# SPC1169 register map
File version: 2022071043481212
CPU: cm4 r1p0, little endian, no MPU, FPU, 4 interrupt priority bits
Registers are 32-bit, read-write, reset 0x0 unless marked. A register's access mark holds for its fields unless they carry their own. Offsets are from the block's base; [hi:lo] are bit positions; {n}, {i} and the like mark numbered series; 'fields as' and 'values as' point back to an identical list.

## PWM0 (part 2 of 2)
Base 0x40002000
Same registers: PWM1 0x40002100, PWM2 0x40002200, PWM3 0x40002300
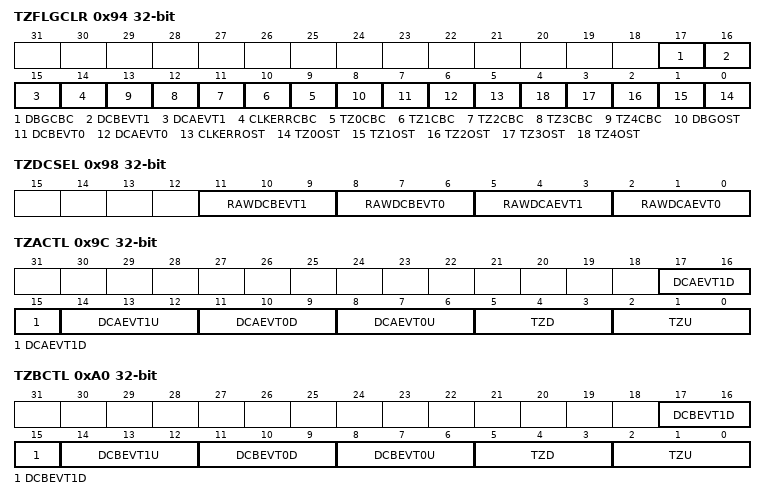
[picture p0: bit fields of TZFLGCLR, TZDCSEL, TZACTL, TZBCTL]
0x94 TZFLGCLR — Trip-Zone Flag Clear Register
  [all] fields
    0=NO_EFFECT (Write a 0 has no effect. Always reads back a 0); 1=CLEAR (Write a 1 clears the latched status. This bit is self-cleared to 0)
  [17] DBGCBC — Latched JTAG debug cycle-by-cycle trip event flag clear
  [16] DCBEVT1 — Latched digital compare B event 1 cycle-by-cycle trip flag clear
  [15] DCAEVT1 — Latched digital compare A event 1 cycle-by-cycle trip flag clear
  [14] CLKERRCBC — Latched clock error cycle-by-cycle trip event flag clear
  [n+9] TZ{n}CBC (n=0..4) — Latched TZ{n} cycle-by-cycle trip event flag clear
  [8] DBGOST — Latched JTAG debug one-shot trip event flag clear
  [7] DCBEVT0 — Latched digital output B event 0 one-shot trip flag clear
  [6] DCAEVT0 — Latched digital output A event 0 one-shot trip flag clear
  [5] CLKERROST — Latched clock error one-shot trip event flag clear
  [n] TZ{n}OST (n=0..4) — Latched TZ{n} one-shot trip event flag clear
0x98 TZDCSEL — Trip-Zone Digital Compare Event Select Register
  [11:9] RAWDCBEVT1 — Raw digital compare B event 1 option
    0=DISABLE (Event disabled); 1=DCBH_X_DCBL_LOW (DCBL=low, DCBH=don't care); 2=DCBH_X_DCBL_HIGH (DCBL=high, DCBH=don't care); 3=DCBH_LOW_DCBL_X (DCBL=don't care, DCBH=low); 4=DCBH_HIGH_DCBL_X (DCBL=don't care, DCBH=high); 5=DCBH_HIGH_DCBL_LOW (DCBL=low, DCBH=high); 6=DCBH_LOW_DCBL_HIGH (DCBL=high, DCBH=low); 7=DCBH_HIGH_DCBL_HIGH (DCBL=high, DCBH=high)
  [8:6] RAWDCBEVT0 — Raw digital compare B event 0 option
    values as RAWDCBEVT1
  [5:3] RAWDCAEVT1 — Raw digital compare A event 1 option
    0=DISABLE (Event disabled); 1=DCAH_X_DCAL_LOW (DCAL=low, DCAH=don't care); 2=DCAH_X_DCAL_HIGH (DCAL=high, DCAH=don't care); 3=DCAH_LOW_DCAL_X (DCAL=don't care, DCAH=low); 4=DCAH_HIGH_DCAL_X (DCAL=don't care, DCAH=high); 5=DCAH_HIGH_DCAL_LOW (DCAL=low, DCAH=high); 6=DCAH_LOW_DCAL_HIGH (DCAL=high, DCAH=low); 7=DCAH_HIGH_DCAL_HIGH (DCAL=high, DCAH=high)
  [2:0] RAWDCAEVT0 — Raw digital compare A event 0 option
    values as RAWDCAEVT1
0x9C TZACTL — Trip-Zone Output A Control Register
  [all] fields
    0=TRI_STATE (Set output A to high-impedance); 1=SET_LOW (Force output A to low state); 2=SET_HIGH (Force output A to high state); 3=TOGGLE (Force output A to invert current state (high->low, low->high)); 7=DO_NOTHING (Do nothing for output A)
  [17:15] DCAEVT1D — Action on output A when a digital compare A event 1 occurs and TBCNT is counting down
  [14:12] DCAEVT1U — Action on output A when a digital compare A event 1 occurs and TBCNT is counting up
  [11:9] DCAEVT0D — Action on output A when a digital compare A event 0 occurs and TBCNT is counting down
  [8:6] DCAEVT0U — Action on output A when a digital compare A event 0 occurs and TBCNT is counting up
  [5:3] TZD — Action on output A when a trip event occurs and TBCNT is counting down
  [2:0] TZU — Action on output A when a trip event occurs and TBCNT is counting up
0xA0 TZBCTL — Trip-Zone Ouput B Control Register
  [17:15] DCBEVT1D — Action on output B when a digital compare B event 1 occurs and TBCNT is counting down
    0=TRI_STATE (Set output B to high-impedance); 1=SET_HIGH (Force output B to high state); 2=SET_LOW (Force output B to low state); 3=TOGGLE (Force output B to invert current state (high->low, low->high)); 7=DO_NOTHING (Do nothing for output B)
  [14:12] DCBEVT1U — Action on output B when a digital compare B event 1 occurs and TBCNT is counting up
    0=TRI_STATE (Set output B to high-impedance); 1=SET_LOW (Force output B to low state); 2=SET_HIGH (Force output B to high state); 3=TOGGLE (Force output B to invert current state (high->low, low->high)); 7=DO_NOTHING (Do nothing for output B)
  [11:9] DCBEVT0D — Action on output B when a digital compare B event 0 occurs and TBCNT is counting down
    values as DCBEVT1U
  [8:6] DCBEVT0U — Action on output B when a digital compare B event 0 occurs and TBCNT is counting up
    values as DCBEVT1U
  [5:3] TZD — Action on output B when a trip event occurs and TBCNT is counting down
    values as DCBEVT1U
  [2:0] TZU — Action on output B when a trip event occurs and TBCNT is counting up
    values as DCBEVT1U
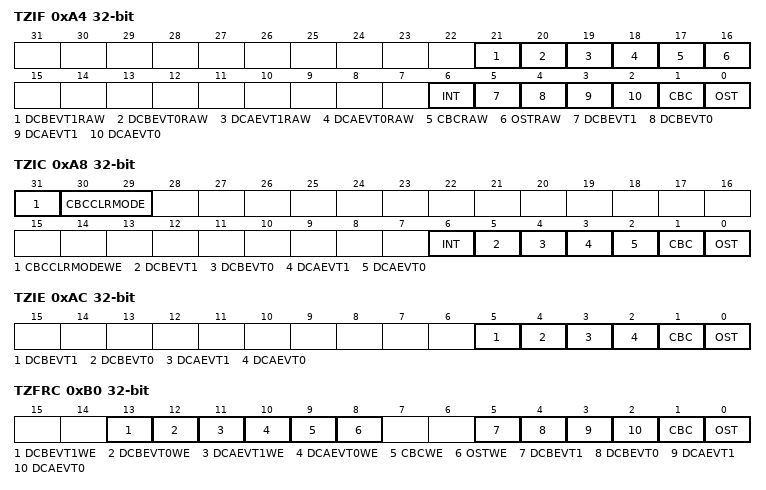
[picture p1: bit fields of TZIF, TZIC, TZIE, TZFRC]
0xA4 TZIF ro — Trip-Zone Interrupt Flag Register
  [21] DCBEVT1RAW — Digital compare B event 1 raw interrupt flag
    0=NOT_OCCUR (DCBEVT1 event does not occur); 1=OCCUR (DCBEVT1 event occurred. It is cleared by writing 1 to TZIC.DCBEVT1.)
  [20] DCBEVT0RAW — Digital compare B event 0 raw interrupt flag
    0=NOT_OCCUR (DCBEVT0 event does not occur); 1=OCCUR (DCBEVT0 event occurred. It is cleared by writing 1 to TZIC.DCBEVT0.)
  [19] DCAEVT1RAW — Digital compare A event 1 raw interrupt flag
    0=NOT_OCCUR (DCAEVT1 event does not occur); 1=OCCUR (DCAEVT1 event occurred. It is cleared by writing 1 to TZIC.DCAEVT1.)
  [18] DCAEVT0RAW — Digital compare A event 0 raw interrupt flag
    0=NOT_OCCUR (DCAEVT0 event does not occur); 1=OCCUR (DCAEVT0 event occurred. It is cleared by writing 1 to TZIC.DCAEVT0.)
  [17] CBCRAW — Cycle-by-cycle trip event raw interrupt flag
    0=NOT_OCCUR (Cycle-by-cycle trip event does not occur); 1=OCCUR (Cycle-by-cycle trip event occurred. It will remain set until it is manually cleared by wring 1 to TZCLR.CBC. If the cycle-by-cycle trip event is still present, it will be immediately set again.)
  [16] OSTRAW — One-shot trip event raw interrupt flag
    0=NOT_OCCUR (One-shot trip event does not occur); 1=OCCUR (One-shot trip event occurred. It is cleared by writing 1 to TZCLR.OST.)
  [6] INT — Global trip interrupt flag
    0=NOT_OCCUR (No trip-zone interrupt has been generated); 1=OCCUR (Trip-zone interrupt was generated and issued to the CPU. No further trip-zone interrupt will be generated until this flag is cleared by writing 1 to TZIC.INT)
  [5] DCBEVT1 — Digital compare B event 1 interrupt flag. This bit is always 0 if TZIE.DCBEVT1=0
    0=NOT_OCCUR (DCBEVT interrupt does not occur); 1=OCCUR (DCBEVT1 interrupt occurred. Further DCBEVT1 event will not trigger interrupt until this bit is cleared by writing 1 to TZIC.DCBEVT1.)
  [4] DCBEVT0 — Digital compare B event 0 interrupt flag. This bit is always 0 if TZIE.DCAEVT1=0
    0=NOT_OCCUR (DCBEVT0 interrupt does not occur); 1=OCCUR (DCBEVT0 interrupt occured. Further DCBEVT0 event will not trigger interrupt until this bit is cleared by writing 1 to TZIC.DCBEVT0.)
  [3] DCAEVT1 — Digital compare A event 1 interrupt flag. This bit is always 0 if TZIE.DCAEVT1=0
    0=NOT_OCCUR (DCAEVT1 did not occur); 1=OCCUR (DCAEVT1 has occurred. It is cleared by writing 1 to TZIC.DCAEVT1.)
  [2] DCAEVT0 — Digital compare A event 0 interrupt flag. This bit is always 0 if TZIE.DCAEVT0=0
    0=NOT_OCCUR (DCAEVT0 did not occur); 1=OCCUR (DCAEVT0 has occurred. It is cleared by writing 1 to TZIC.DCAEVT0.)
  [1] CBC — Cycle-by-cycle trip event interrupt flag. This bit is always 0 if TZIE.CBC=0
    0=NOT_OCCUR (Cycle-by-cycle trip interrupt does not occur); 1=OCCUR (Cycle-by-cycle trip interrupt occurred. Further event will not trigger interrupt until this bit is cleared by wring 1 to TZCLR.CBC. If the cycle-by-cycle trip event is still present when the CBC bit is cleared, it will be immediately set again and a new interrupt is generated.)
  [0] OST — One-shot trip event interrupt flag. This bit is always 0 if TZIE.OST=0
    0=NOT_OCCUR (One-shot trip interrupt does not occur); 1=OCCUR (One-shot trip interrupt occurred. Further event will not trigger interrupt until this bit is cleared by writing 1 to TZCLR.OST.)
0xA8 TZIC — Trip-Zone Clear Register
  [31] CBCCLRMODEWE — Latched CBC trip status clear mode write enable
    0=NO_EFFECT (Write 0 has no effect and always reads back 0); 1=ENABLE (Write 1 enables concurrent write to CBCCLRMODE bit. This bit is self-cleared to 0)
  [30:29] CBCCLRMODE — Latched CBC trip status clear mode. This bit is writable only when CBCCLRMODEWE bit is 1 and PWMREGKEY=0x1acce551
    0=CLEAR_ON_ZERO (Clear CBC trip on TBCNT=0); 1=CLEAR_ON_PERIOD (Clear CBC trip on TBCNT=TBPRD); 2=CLEAR_ON_ZERO_PERIOD (Clear CBC trip on TBCNT=0 or TBCNT=TBPRD); 3=CLEAR_DISABLE (Clear disabled. i.e. Never clear the CBC trip)
  [6] INT — Clear global interrupt status flag
    0=NO_EFFECT (Write 0 has no effect and always reads back 0); 1=CLEAR (Write a 1 clears TZIF.INT and TZ interrupt)
  [5] DCBEVT1 — Clear digital compare B event 1 status flag
    0=NO_EFFECT (Write 0 has no effect and always reads back 0); 1=CLEAR (Write a 1 clears TZIF.DCBEVT1)
  [4] DCBEVT0 — Clear digital compare B event 0 status flag
    0=NO_EFFECT (Write 0 has no effect and always reads back 0); 1=CLEAR (Write a 1 clears TZIF.DCBEVT0)
  [3] DCAEVT1 — Clear digital compare A event 1 status flag
    0=NO_EFFECT (Write 0 has no effect and always reads back 0); 1=CLEAR (Write a 1 clears TZIF.DCAEVT1)
  [2] DCAEVT0 — Clear digital compare A event 0 status flag
    0=NO_EFFECT (Write 0 has no effect and always reads back 0); 1=CLEAR (Write a 1 clears TZIF.DCAEVT0)
  [1] CBC — Clear cycle-by-cycle trip status flag
    0=NO_EFFECT (Write 0 has no effect and always reads back 0); 1=CLEAR (Write a 1 clears TZIF.CBC)
  [0] OST — Clear one-shot trip status flag
    0=NO_EFFECT (Write 0 has no effect and always reads back 0); 1=CLEAR (Write a 1 clears TZIF.OST)
0xAC TZIE — Trip-Zone Interrupt Enable Register
  [all] fields
    0=DISABLE; 1=ENABLE
  [5] DCBEVT1 — Digital compare B event 1 interrupt enable
  [4] DCBEVT0 — Digital compare B event 0 interrupt enable
  [3] DCAEVT1 — Digital compare A event 1 interrupt enable
  [2] DCAEVT0 — Digital compare A event 0 interrupt enable
  [1] CBC — Cycle-by-cycle trip-zone interrupt enable
  [0] OST — One-shot trip-zone interrupt enable
0xB0 TZFRC — Trip-Zone Force Register
  [13] DCBEVT1WE — DCBEVT1 bit write enable
    0=DISABLE; 1=ENABLE
  [12] DCBEVT0WE — DCBEVT0 bit write enable
    0=DISABLE; 1=ENABLE
  [11] DCAEVT1WE — DCAEVT1 bit write enable
    0=DISABLE; 1=ENABLE
  [10] DCAEVT0WE — DAAEVT0 bit write enable
    0=DISABLE; 1=ENABLE
  [9] CBCWE — CBC bit write enable
    0=DISABLE; 1=ENABLE
  [8] OSTWE — OST bit write enable
    0=DISABLE; 1=ENABLE
  [5] DCBEVT1 — Software force a digital compare B event 1. DCBEVT1WE bit should be written 1 at the same time
    0=NO_EFFECT (Write 0 has no effect and always reads back 0); 1=FORCE (Write a 1 forces a digital compare B event 1 and sets TZIF bits)
  [4] DCBEVT0 — Software force a digital compare B event 0. DCBEVT0WE bit should be written 1 at the same time
    0=NO_EFFECT (Write 0 has no effect and always reads back 0); 1=FORCE (Write a 1 forces a digital compare B event 0 and sets TZIF bits)
  [3] DCAEVT1 — Software force a digital compare A event 1. DCAEVT1WE bit should be written 1 at the same time
    0=NO_EFFECT (Write 0 has no effect and always reads back 0); 1=FORCE (Write a 1 forces a digital compare A event 1 and sets TZIF bits)
  [2] DCAEVT0 — Software force a digital compare A event 0. DCAEVT0WE bit should be written 1 at the same time
    0=NO_EFFECT (Write 0 has no effect and always reads back 0); 1=FORCE (Write a 1 forces a digital compare A event 0 and sets TZIF bits)
  [1] CBC — Software force a cycle-by-cycle trip event. CBCWE bit should be written 1 at the same time
    0=NO_EFFECT (Write 0 has no effect and always reads back 0); 1=FORCE (Write a 1 forces a cycle-by-cycle trip event and sets TZIF bits)
  [0] OST — Software force a one-shot trip event. OSTWE bit should be written 1 at the same time
    0=NO_EFFECT (Write 0 has no effect and always reads back 0); 1=FORCE (Write a 1 forces a one-shot trip event and sets TZIF bits)
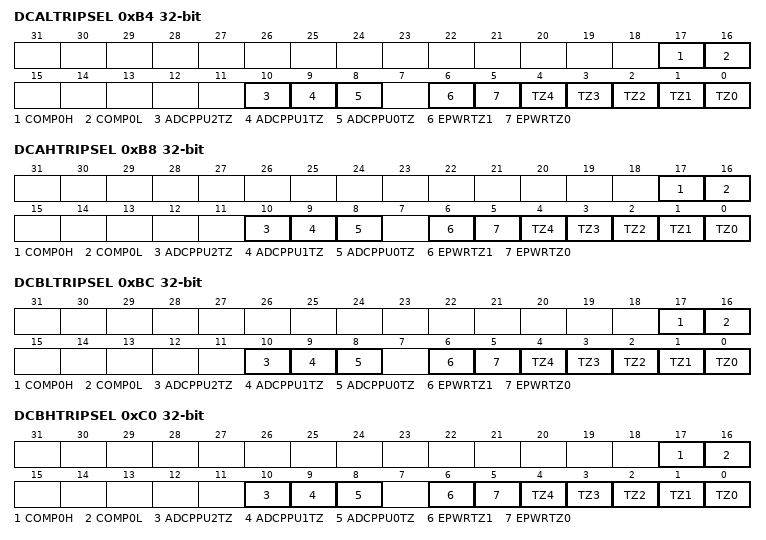
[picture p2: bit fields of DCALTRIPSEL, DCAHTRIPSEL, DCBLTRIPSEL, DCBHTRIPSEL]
0xB4 DCALTRIPSEL — Digital Compare AL Trip Select Register
  [all] fields
    0=DISABLE; 1=ENABLE
  [17] COMP0H — Enable COMPH as DCAL trip event (ORed)
  [16] COMP0L — Enable COMPL as DCAL trip event (ORed)
  [10] ADCPPU2TZ — Enable ADCPPU2TZ as DCAL trip event (ORed)
  [9] ADCPPU1TZ — Enable ADCPPU1TZ as DCAL trip event (ORed)
  [8] ADCPPU0TZ — Enable ADCPPU0TZ as DCAL trip event (ORed)
  [6] EPWRTZ1 — Enable EPWRTZ1 as DCAL trip event (ORed)
  [5] EPWRTZ0 — Enable EPWRTZ0 as DCAL trip event (ORed)
  [n] TZ{n} (n=0..4) — Enable TZ{n} as DCAL trip event (ORed)
0xB8 DCAHTRIPSEL — Digital Compare AH Trip Select Register
  [all] fields
    0=DISABLE; 1=ENABLE
  [17] COMP0H — Enable COMPH as DCAH trip event (ORed)
  [16] COMP0L — Enable COMPL as DCAH trip event (ORed)
  [10] ADCPPU2TZ — Enable ADCPPU2TZ as DCAH trip event (ORed)
  [9] ADCPPU1TZ — Enable ADCPPU1TZ as DCAH trip event (ORed)
  [8] ADCPPU0TZ — Enable ADCPPU0TZ as DCAH trip event (ORed)
  [6] EPWRTZ1 — Enable EPWRTZ1 as DCAH trip event (ORed)
  [5] EPWRTZ0 — Enable EPWRTZ0 as DCAH trip event (ORed)
  [n] TZ{n} (n=0..4) — Enable TZ{n} as DCAH trip event (ORed)
0xBC DCBLTRIPSEL — Digital Compare BL Trip Select Register
  [all] fields
    0=DISABLE; 1=ENABLE
  [17] COMP0H — Enable COMPH as DCBL trip event (ORed)
  [16] COMP0L — Enable COMPL as DCBL trip event (ORed)
  [10] ADCPPU2TZ — Enable ADCPPU2TZ as DCBL trip event (ORed)
  [9] ADCPPU1TZ — Enable ADCPPU1TZ as DCBL trip event (ORed)
  [8] ADCPPU0TZ — Enable ADCPPU0TZ as DCBL trip event (ORed)
  [6] EPWRTZ1 — Enable EPWRTZ1 as DCBL trip event (ORed)
  [5] EPWRTZ0 — Enable EPWRTZ0 as DCBL trip event (ORed)
  [n] TZ{n} (n=0..4) — Enable TZ{n} as DCBL trip event (ORed)
0xC0 DCBHTRIPSEL — Digital Compare BH Trip Select Register
  [all] fields
    0=DISABLE; 1=ENABLE
  [17] COMP0H — Enable COMPH as DCBH trip event (ORed)
  [16] COMP0L — Enable COMPL as DCBH trip event (ORed)
  [10] ADCPPU2TZ — Enable ADCPPU2TZ as DCBH trip event (ORed)
  [9] ADCPPU1TZ — Enable ADCPPU1TZ as DCBH trip event (ORed)
  [8] ADCPPU0TZ — Enable ADCPPU0TZ as DCBH trip event (ORed)
  [6] EPWRTZ1 — Enable EPWRTZ1 as DCBH trip event (ORed)
  [5] EPWRTZ0 — Enable EPWRTZ0 as DCBH trip event (ORed)
  [n] TZ{n} (n=0..4) — Enable TZ{n} as DCBH trip event (ORed)
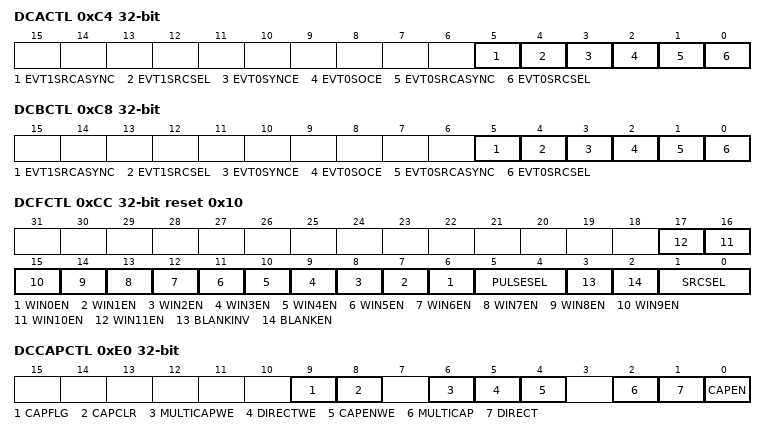
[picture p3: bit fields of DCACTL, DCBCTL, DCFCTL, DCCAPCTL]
0xC4 DCACTL — Digital Compare A Control Register
  [5] EVT1SRCASYNC — DCAEVT1 source signal is asynchronous/synchronous
    0=DCAEVT1_SYNC (Synchronous); 1=DCAEVT1_ASYNC (Asynchronous)
  [4] EVT1SRCSEL — DCAEVT1 source signal select
    0=RAWDCAEVT1 (Source signal is raw DCAEVT1); 1=DCEVTFILT (Source signal is DCEVTFILT)
  [3] EVT0SYNCE — DCAEVT0 SYNC generation
    0=DISABLE; 1=ENABLE
  [2] EVT0SOCE — DCAEVT0 SOC generation
    0=DISABLE; 1=ENABLE
  [1] EVT0SRCASYNC — DCAEVT0 source signal is asynchronous/synchronous (1/0)
    0=DCAEVT0_SYNC (Synchronous); 1=DCAEVT0_ASYNC (Asynchronous)
  [0] EVT0SRCSEL — DCAEVT0 source signal select
    0=RAWDCAEVT0 (Source signal is raw DCAEVT0); 1=DCEVTFILT (Source signal is DCEVTFILT)
0xC8 DCBCTL — Digital Compare B Control Register
  [5] EVT1SRCASYNC — DCBEVT1 source signal is asynchronous/synchronous (1/0)
    0=DCBEVT1_SYNC (Synchronous); 1=DCBEVT1_ASYNC (Asynchronous)
  [4] EVT1SRCSEL — DCBEVT1 source signal select
    0=RAWDCBEVT1 (Source signal is raw DCBEVT1); 1=DCEVTFILT (Source signal is DCEVTFILT)
  [3] EVT0SYNCE — DCBEVT0 SYNC generation
    0=DISABLE; 1=ENABLE
  [2] EVT0SOCE — DCBEVT0 SOC generation
    0=DISABLE; 1=ENABLE
  [1] EVT0SRCASYNC — DCBEVT0 source signal is asynchronous/synchronous
    0=DCBEVT0_SYNC (Synchronous); 1=DCBEVT0_ASYNC (Asynchronous)
  [0] EVT0SRCSEL — DCBEVT0 source signal select
    0=RAWDCBEVT0 (Source signal is raw DCBEVT0); 1=DCEVTFILT (Source signal is DCEVTFILT)
0xCC DCFCTL reset 0x10 — Digital Compare Filter Register
  [n+6] WIN{n}EN (n=0..11) — Enable blank window from PWM{n} (ORed)
    0=DISABLE; 1=ENABLE
  [5:4] PULSESEL — Pulse select for blanking and capture alignment for this module
    0=ALIGN_ON_ZERO (Align on TBCNT=0); 1=ALIGN_ON_PERIOD (Align on TBCNT=TBPRD); 2=ALIGN_ON_ZERO_PERIOD (Align on TBCNT=0 or TBCNT=TBPRD)
  [3] BLANKINV — blanking window inversion
    0=DISABLE; 1=ENABLE
  [2] BLANKEN — blanking window
    0=DISABLE; 1=ENABLE
  [1:0] SRCSEL — DCEVTFILT signal source select
    0=RAWDCAEVT0 (Source is raw DCAEVT0); 1=RAWDCAEVT1 (Source is raw DCAEVT1); 2=RAWDCBEVT0 (Source is raw DCBEVT0); 3=RAWDCBEVT1 (Source is raw DCBEVT1)
0xD0 DCFOFFSET — Digital Compare Filter Offset Register
  [15:0] VAL — Blanking window offset. It defines the number of TBCLK cycles from the blanking window reference specified by DCFCTL.PULSESEL to the point when the blanking window is applied.
0xD4 DCFOFFSETCNT ro — Digital Compare Filter Offset Counter Register
  [15:0] VAL — Blanking offset counter. It is read only and indicates the current value of the offset counter. The counter counts down to zero and then stops until it is re-loaded on the next event defined by DCFCTL.PULSESEL.
0xD8 DCFWINDOW — Digital Compare Filter Window Register
  [15:0] VAL — Blanking window width in TBCLK cycles. The blanking window begins when the offset counter expires. When this occurs, the window counter is loaded and begins to count down. If the blanking window is currently active and the offset counter expires, the blanking window counter is restarted. The blanking window can cross a PWM period boundary. No blanking window is generated when it is set to zero.
0xDC DCFWINDOWCNT ro — Digital Compare Filter Window Counter Register
  [15:0] VAL — Blanking window counter. It is read only and indicates the current value of the window counter. The counter counts down to zero and then stops until it is re-loaded when the offset counter reaches zero again.
0xE0 DCCAPCTL — Digital Compare Capture Control Register
  [9] CAPFLG ro — Latched capture flag
    0=NOT_OCCUR (No DC capture event occurred); 1=OCCUR (DC capture event has occurred)
  [8] CAPCLR — Latched capture flag clear
    0=NO_EFFECT (Write 0 has no effect and always reads back 0); 1=CLEAR (Write a 1 clears the latched flag. This bit is self-cleared to 0)
  [6] MULTICAPWE — MULTICAP bit write enable
    0=NO_EFFECT (Write 0 has no effect and always reads back 0); 1=ENABLE (Write 1 enables concurrent write to MULTICAP bit. This bit is self-cleared to 0)
  [5] DIRECTWE — DIRECT bit write enable
    0=NO_EFFECT (Write 0 has no effect and always reads back 0); 1=ENABLE (Write 1 enables concurrent write to DIRECT bit. This bit is self-cleared to 0)
  [4] CAPENWE — CAPEN bit write enable
    0=NO_EFFECT (Write 0 has no effect and always reads back 0); 1=ENABLE (Write 1 enables concurrent write to CAPEN bit. This bit is self-cleared to 0)
  [2] MULTICAP — DCCAP multiple capture mode
    0=DISABLE (Capture only once upon the first event in each cycle until next cycle is started by the pulse defined in DCFCTL.PULSESEL); 1=ENABLE (Capture upon every events and always keep the latest captured value)
  [1] DIRECT — DCCAP direct load mode
    0=DISABLE (Shadow mode. The DCCAP active value is copied to shadow register on a TBCNT=TBPRD or TBCNT=zero event as defined by DCFCTL.PULSESEL. Reads of the DCCAP register always returns the shadow register contents.); 1=ENABLE (Direct mode. Reads of the DCCAP register always returns the active value.)
  [0] CAPEN — TBCNT counter capture enable
    0=DISABLE; 1=ENABLE
0xE4 DCCAP ro — Digital Compare Counter Capture Register
  [15:0] VAL — Captured TBCNT value upon a rising-edge of DCEVTFLT. In shadow mode, the captured value is copied to the shadow register on a TBCNT=TBPRD or TBCNT=zero event as defined by DCFCTL.PULSESEL. Reads of the DCCAP register always returns the shadow register contents. In direct mode, reads of the DCCAP register always returns the active value.
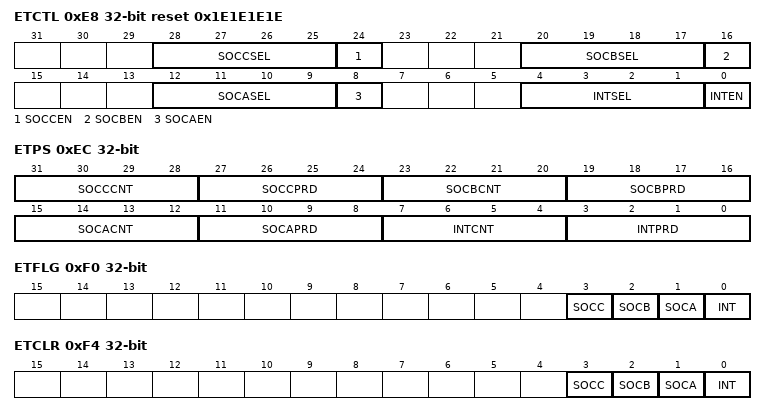
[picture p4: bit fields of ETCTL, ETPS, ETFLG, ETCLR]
0xE8 ETCTL reset 0x1E1E1E1E — Event-Trigger Control Register
  [28:25] SOCCSEL — SOCC event select
    0=TBCNT_EQU_ZERO (Enable event TBCNT=0); 1=TBCNT_EQU_PERIOD (Enable event TBCNT=TBPRD); 2=TBCNT_EQU_ZERO_PERIOD (Enable event TBCNT=0 or TBCNT=TBPRD); 3=TBCNT_EQU_CMPA_UP (Enable event TBCNT=CMPA when TBCNT is counting up); 4=TBCNT_EQU_CMPA_DOWN (Enable event TBCNT=CMPA when TBCNT is counting down); 5=TBCNT_EQU_CMPB_UP (Enable event TBCNT=CMPB when TBCNT is counting up); 6=TBCNT_EQU_CMPB_DOWN (Enable event TBCNT=CMPB when TBCNT is counting down); 7=TBCNT_EQU_CMPC_UP (Enable event TBCNT=CMPC when TBCNT is counting up); 8=TBCNT_EQU_CMPC_DOWN (Enable event TBCNT=CMPC when TBCNT is counting down); 9=TBCNT_EQU_CMPD_UP (Enable event TBCNT=CMPD when TBCNT is counting up); 10=TBCNT_EQU_CMPD_DOWN (Enable event TBCNT=CMPD when TBCNT is counting down); 11=DCAEVT0_SOC (Enable DCAEVT0.SOC event); 12=DCBEVT0_SOC (Enable DCBEVT0.SOC event)
  [24] SOCCEN — ADC start of conversion C (SOCC) pulse enable
    0=DISABLE; 1=ENABLE
  [20:17] SOCBSEL — SOCB event select
    0=TBCNT_EQU_ZERO (Select event TBCNT=0); 1=TBCNT_EQU_PERIOD (Select event TBCNT=TBPRD); 2=TBCNT_EQU_ZERO_PERIOD (Select event TBCNT=0 or TBCNT=TBPRD); 3=TBCNT_EQU_CMPA_UP (Select event TBCNT=CMPA when TBCNT is counting up); 4=TBCNT_EQU_CMPA_DOWN (Select event TBCNT=CMPA when TBCNT is counting down); 5=TBCNT_EQU_CMPB_UP (Select event TBCNT=CMPB when TBCNT is counting up); 6=TBCNT_EQU_CMPB_DOWN (Select event TBCNT=CMPB when TBCNT is counting down); 7=TBCNT_EQU_CMPC_UP (Select event TBCNT=CMPC when TBCNT is counting up); 8=TBCNT_EQU_CMPC_DOWN (Select event TBCNT=CMPC when TBCNT is counting down); 9=TBCNT_EQU_CMPD_UP (Select event TBCNT=CMPD when TBCNT is counting up); 10=TBCNT_EQU_CMPD_DOWN (Select event TBCNT=CMPD when TBCNT is counting down); 11=DCAEVT0_SOC (Select DCAEVT0.SOC event); 12=DCBEVT0_SOC (Select DCBEVT0.SOC event)
  [16] SOCBEN — ADC start of conversion B (SOCB) pulse enable
    0=DISABLE; 1=ENABLE
  [12:9] SOCASEL — SOCA event select
    values as SOCBSEL
  [8] SOCAEN — ADC start of conversion A (SOCA) pulse enable
    0=DISABLE; 1=ENABLE
  [4:1] INTSEL — PWM interrupt select
    values as SOCBSEL
  [0] INTEN — PWM interrupt enable
    0=DISABLE; 1=ENABLE
0xEC ETPS — Event-Trigger Prescale Register
  [31:28] SOCCCNT — PWM ADC start-of-conversion C event (SOCC) counter. It indicates how many selected ETSEL.SOCCSEL events have occurred. It is automatically cleared when an SOCC pulse is generated. It can be initialized via write.
    0=NO_EVENT_OCCUR (No events have occurred); 1=1_EVENT_OCCUR (1 event has occurred); {v}={v}_EVENT_OCCUR ({v} events have occurred) (v=2..15)
  [27:24] SOCCPRD — PWM ADC start-of-conversion C event (SOCC) period select. SOCC is generated upon SOCCPRD<=SOCCCNT and ETCTL[SOCCEN]=1. No SOCC will be generated if SOCCPRD=0
    0=GEN_SOCC_DISABLE (Disable SOCC event counter. No SOCC pulse will be generated.); 1=GEN_SOCC_ON_1ST_EVENT (Generate SOCC pulse when ETPS.SOCCCNT=0001 (first event)); 2=GEN_SOCC_ON_2ND_EVENT (Generate SOCC pulse when ETPS.SOCCCNT=0010 (second event)); 3=GEN_SOCC_ON_3RD_EVENT (Generate SOCC pulse when ETPS.SOCCCNT=0011 (third event)); 4=GEN_SOCC_ON_4TH_EVENT (Generate SOCC pulse when ETPS.SOCCCNT=0100 (fourth event)); 5=GEN_SOCC_ON_5TH_EVENT (Generate SOCC pulse when ETPS.SOCCCNT=0101 (fifth event)); 6=GEN_SOCC_ON_6TH_EVENT (Generate SOCC pulse when ETPS.SOCCCNT=0110(sixth event)); 7=GEN_SOCC_ON_7TH_EVENT (Generate SOCC pulse when ETPS.SOCCCNT=0111 (seventh event)); 8=GEN_SOCC_ON_8TH_EVENT (Generate SOCC pulse when ETPS.SOCCCNT=1000 (eighth event)); 9=GEN_SOCC_ON_9TH_EVENT (Generate SOCC pulse when ETPS.SOCCCNT=1001 (ninth event)); 10=GEN_SOCC_ON_10TH_EVENT (Generate SOCC pulse when ETPS.SOCCCNT=1010 (tenth event)); 11=GEN_SOCC_ON_11TH_EVENT (Generate SOCC pulse when ETPS.SOCCCNT=1011 (eleventh event)); 12=GEN_SOCC_ON_12TH_EVENT (Generate SOCC pulse when ETPS.SOCCCNT=1100(twelfth event)); 13=GEN_SOCC_ON_13TH_EVENT (Generate SOCC pulse when ETPS.SOCCCNT=1101 (thirteenth event)); 14=GEN_SOCC_ON_14TH_EVENT (Generate SOCC pulse when ETPS.SOCCCNT=1110(fourteenth event)); 15=GEN_SOCC_ON_15TH_EVENT (Generate SOCC pulse when ETPS.SOCCCNT=1111 (fifteenth event))
  [23:20] SOCBCNT — PWM ADC start-of-conversion B event (SOCB) counter. It indicates how many selected ETSEL.SOCBSEL events have occurred. It is automatically cleared when an SOCB pulse is generated. It can be initialized via write.
    values as SOCCCNT
  [19:16] SOCBPRD — PWM ADC start-of-conversion B event (SOCB) period select. SOCB is generated upon SOCBPRD<=SOCBCNT and ETCTL[SOCBEN]=1. No SOCB will be generated if SOCBPRD=0
    0=GEN_SOCB_DISABLE (Disable SOCB event counter. No SOCB pulse will be generated.); 1=GEN_SOCB_ON_1ST_EVENT (Generate SOCB pulse when ETPS.SOCBCNT=0001 (first event)); 2=GEN_SOCB_ON_2ND_EVENT (Generate SOCB pulse when ETPS.SOCBCNT=0010 (second event)); 3=GEN_SOCB_ON_3RD_EVENT (Generate SOCB pulse when ETPS.SOCBCNT=0011 (third event)); 4=GEN_SOCB_ON_4TH_EVENT (Generate SOCB pulse when ETPS.SOCBCNT=0100 (fourth event)); 5=GEN_SOCB_ON_5TH_EVENT (Generate SOCB pulse when ETPS.SOCBCNT=0101 (fifth event)); 6=GEN_SOCB_ON_6TH_EVENT (Generate SOCB pulse when ETPS.SOCBCNT=0110(sixth event)); 7=GEN_SOCB_ON_7TH_EVENT (Generate SOCB pulse when ETPS.SOCBCNT=0111 (seventh event)); 8=GEN_SOCB_ON_8TH_EVENT (Generate SOCB pulse when ETPS.SOCBCNT=1000 (eighth event)); 9=GEN_SOCB_ON_9TH_EVENT (Generate SOCB pulse when ETPS.SOCBCNT=1001 (ninth event)); 10=GEN_SOCB_ON_10TH_EVENT (Generate SOCB pulse when ETPS.SOCBCNT=1010 (tenth event)); 11=GEN_SOCB_ON_11TH_EVENT (Generate SOCB pulse when ETPS.SOCBCNT=1011 (eleventh event)); 12=GEN_SOCB_ON_12TH_EVENT (Generate SOCB pulse when ETPS.SOCBCNT=1100(twelfth event)); 13=GEN_SOCB_ON_13TH_EVENT (Generate SOCB pulse when ETPS.SOCBCNT=1101 (thirteenth event)); 14=GEN_SOCB_ON_14TH_EVENT (Generate SOCB pulse when ETPS.SOCBCNT=1110(fourteenth event)); 15=GEN_SOCB_ON_15TH_EVENT (Generate SOCB pulse when ETPS.SOCBCNT=1111 (fifteenth event))
  [15:12] SOCACNT — PWM ADC start-of-conversion A event (SOCA) counter. It indicates how many selected ETSEL.SOCASEL events have occurred. It is automatically cleared when an SOCA pulse is generated. It can be initialized via write.
    values as SOCCCNT
  [11:8] SOCAPRD — PWM ADC start-of-conversion A event (SOCA) period select. SOCA is generated upon SOCAPRD<=SOCACNT and ETCTL[SOCAEN]=1. No SOCA will be generated if SOCAPRD=0
    0=GEN_SOCA_DISABLE (Disable SOCA event counter. No SOCA pulse will be generated.); 1=GEN_SOCA_ON_1ST_EVENT (Generate SOCA pulse when ETPS.SOCACNT=01 (first event)); 2=GEN_SOCA_ON_2ND_EVENT (Generate SOCA pulse when ETPS.SOCACNT=10 (second event)); 3=GEN_SOCA_ON_3RD_EVENT (Generate SOCA pulse when ETPS.SOCACNT=11 (third event)); 4=GEN_SOCA_ON_4TH_EVENT (Generate SOCA pulse when ETPS.SOCACNT=0100 (fourth event)); 5=GEN_SOCA_ON_5TH_EVENT (Generate SOCA pulse when ETPS.SOCACNT=0101 (fifth event)); 6=GEN_SOCA_ON_6TH_EVENT (Generate SOCA pulse when ETPS.SOCACNT=0110(sixth event)); 7=GEN_SOCA_ON_7TH_EVENT (Generate SOCA pulse when ETPS.SOCACNT=0111 (seventh event)); 8=GEN_SOCA_ON_8TH_EVENT (Generate SOCA pulse when ETPS.SOCACNT=1000 (eighth event)); 9=GEN_SOCA_ON_9TH_EVENT (Generate SOCA pulse when ETPS.SOCACNT=1001 (ninth event)); 10=GEN_SOCA_ON_10TH_EVENT (Generate SOCA pulse when ETPS.SOCACNT=1010 (tenth event)); 11=GEN_SOCA_ON_11TH_EVENT (Generate SOCA pulse when ETPS.SOCACNT=1011 (eleventh event)); 12=GEN_SOCA_ON_12TH_EVENT (Generate SOCA pulse when ETPS.SOCACNT=1100(twelfth event)); 13=GEN_SOCA_ON_13TH_EVENT (Generate SOCA pulse when ETPS.SOCACNT=1101 (thirteenth event)); 14=GEN_SOCA_ON_14TH_EVENT (Generate SOCA pulse when ETPS.SOCACNT=1110(fourteenth event)); 15=GEN_SOCA_ON_15TH_EVENT (Generate SOCA pulse when ETPS.SOCACNT=1111 (fifteenth event))
  [7:4] INTCNT — PWM interrupt counter. It indicates how many selected ETSEL.INTSEL events have occurred. It is automatically cleared when an interrupt pulse is generated. It can be initialized via write.
    values as SOCCCNT
  [3:0] INTPRD — PWM interrupt period select. Interrupt is generated upon INTPRD<=INTCNT and ETCTL[INTEN]=1. No interrupt will be generated if INTPRD=0
    0=DISABLE (Disable the interrupt event counter. No interrupt will be generated and ETFRC.INT is ignored.); 1=GEN_INT_ON_1ST_EVENT (Generate an interrupt when ETPS.INTCNT=0001 (first event)); 2=GEN_INT_ON_2ND_EVENT (Generate an interrupt when ETPS.INTCNT=0010 (second event)); 3=GEN_INT_ON_3RD_EVENT (Generate an interrupt when ETPS.INTCNT=0011 (third event)); 4=GEN_INT_ON_4TH_EVENT (Generate an interrupt when ETPS.INTCNT=0100 (fourth event)); 5=GEN_INT_ON_5TH_EVENT (Generate an interrupt when ETPS.INTCNT=0101 (fifth event)); 6=GEN_INT_ON_6TH_EVENT (Generate an interrupt when ETPS.INTCNT=0110(sixth event)); 7=GEN_INT_ON_7TH_EVENT (Generate an interrupt when ETPS.INTCNT=0111 (seventh event)); 8=GEN_INT_ON_8TH_EVENT (Generate an interrupt when ETPS.INTCNT=1000 (eighth event)); 9=GEN_INT_ON_9TH_EVENT (Generate an interrupt when ETPS.INTCNT=1001 (ninth event)); 10=GEN_INT_ON_10TH_EVENT (Generate an interrupt when ETPS.INTCNT=1010 (tenth event)); 11=GEN_INT_ON_11TH_EVENT (Generate an interrupt when ETPS.INTCNT=1011 (eleventh event)); 12=GEN_INT_ON_12TH_EVENT (Generate an interrupt when ETPS.INTCNT=1100(twelfth event)); 13=GEN_INT_ON_13TH_EVENT (Generate an interrupt when ETPS.INTCNT=1101 (thirteenth event)); 14=GEN_INT_ON_14TH_EVENT (Generate an interrupt when ETPS.INTCNT=1110(fourteenth event)); 15=GEN_INT_ON_15TH_EVENT (Generate an interrupt when ETPS.INTCNT=1111 (fifteenth event))
0xF0 ETFLG ro — Event-Trigger Flag Register
  [3] SOCC — Latched PWM ADC start-of-conversion C flag
    0=NOT_OCCUR (Indicates no event occurred); 1=OCCUR (Indicates a SOCC event was generated. The pulse will continue to be generated even if the flag is set.)
  [2] SOCB — Latched PWM ADC start-of-conversion B flag
    0=NOT_OCCUR (Indicates no event occurred); 1=OCCUR (Indicates a SOCB event was generated. The pulse will continue to be generated even if the flag is set.)
  [1] SOCA — Latched PWM ADC start-of-conversion A flag
    0=NOT_OCCUR (Indicates no event occurred); 1=OCCUR (Indicates a SOCA event was generated. The pulse will continue to be generated even if the flag is set.)
  [0] INT — Latched PWM interrupt flag
    0=NOT_OCCUR (Indicates no event occurred); 1=OCCUR (Indicates a PWM interrupt was generated. No further interrupts will be generated until the flag bit is cleared.)
0xF4 ETCLR — Event-Trigger Clear Register
  [3] SOCC — Latched PWM ADC start-of-conversion C flag clear
    0=NO_EFFECT (Write 0 has no effect and always reads back 0); 1=CLEAR (Write a 1 clears ETFLG.SOCC)
  [2] SOCB — Latched PWM ADC start-of-conversion B flag clear
    0=NO_EFFECT (Write 0 has no effect and always reads back 0); 1=CLEAR (Write a 1 clears ETFLG.SOCB)
  [1] SOCA — Latched PWM ADC start-of-conversion A flag clear
    0=NO_EFFECT (Write 0 has no effect and always reads back 0); 1=CLEAR (Write a 1 clears ETFLG.SOCA)
  [0] INT — Latched PWM interrupt flag clear
    0=NO_EFFECT (Write 0 has no effect and always reads back 0); 1=CLEAR (Write a 1 clears ETFLG.INT)
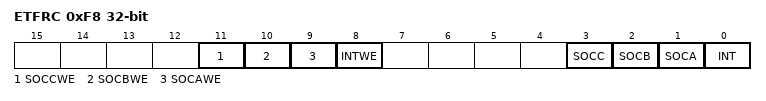
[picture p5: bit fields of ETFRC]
0xF8 ETFRC — Event-Trigger Force Register
  [11] SOCCWE — SOCC bit write enable
    0=DISABLE; 1=ENABLE
  [10] SOCBWE — SOCB bit write enable
    0=DISABLE; 1=ENABLE
  [9] SOCAWE — SOCA bit write enable
    0=DISABLE; 1=ENABLE
  [8] INTWE — INT bit write enable
    0=DISABLE; 1=ENABLE
  [3] SOCC — Software force a start-of-conversion B pulse. SOCCWE bit should be written 1 at the same time. This bit is ignored if ETSEL.SOCCEN=0
    0=NO_EFFECT (Write 0 has no effect and always reads back 0); 1=FORCE (Write a 1 generates an interrupt and sets the ETFLG.SOCC flag)
  [2] SOCB — Software force a start-of-conversion B pulse. SOCBWE bit should be written 1 at the same time. This bit is ignored if ETSEL.SOCBEN=0
    0=NO_EFFECT (Write 0 has no effect and always reads back 0); 1=FORCE (Write a 1 generates an interrupt and sets the ETFLG.SOCB flag)
  [1] SOCA — Software force a start-of-conversion A pulse. SOCAWE bit should be written 1 at the same time. This bit is ignored if ETSEL.SOCAEN=0
    0=NO_EFFECT (Write 0 has no effect and always reads back 0); 1=FORCE (Write a 1 generates an interrupt and sets the ETFLG.SOCA flag)
  [0] INT — Software force a PWM interrupt. INT bit should be written 1 at the same time. This bit is ignored if ETSEL.INTEN=0 or ETPS.INTPRD=00
    0=NO_EFFECT (Write 0 has no effect and always reads back 0); 1=FORCE (Write a 1 generates an interrupt and sets the ETFLG.INT flag)
0xFC PWMREGKEY reset 0x1ACCE551 — PWM Register Write-Allow Key Register
  [31:0] KEY — Write 0x1ACCE551 to unlock protected PWM registers
